VERSION ""

NS_ :

BS_:

BU_: VCU Telemetry ISA_Scale AMS User
VAL_TABLE_ AliveSignal 1 "ONLINE" 0 "OFFLINE" ;

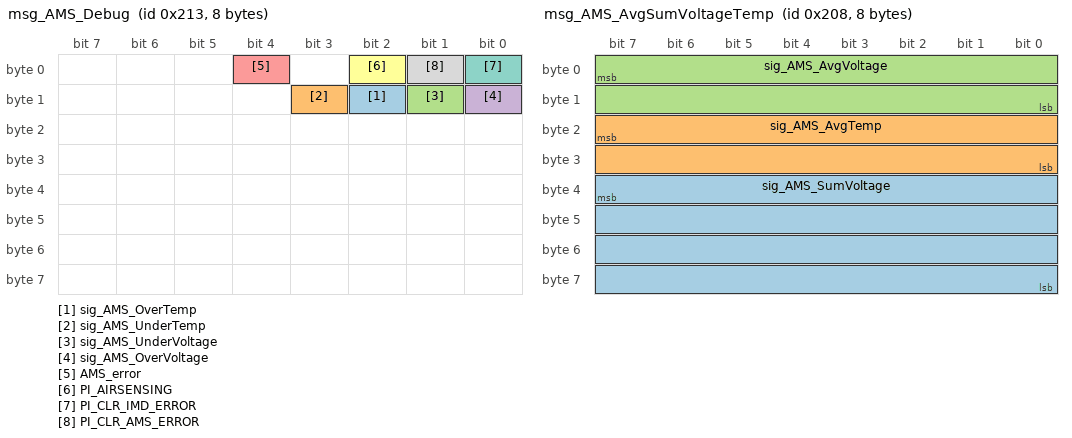
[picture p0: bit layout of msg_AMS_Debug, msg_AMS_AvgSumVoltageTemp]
BO_ 531 msg_AMS_Debug: 8 AMS
 SG_ sig_AMS_OverTemp : 10|1@0+ (1,0) [0|1] ""  VCU
 SG_ sig_AMS_UnderTemp : 11|1@0+ (1,0) [0|1] ""  VCU
 SG_ sig_AMS_UnderVoltage : 9|1@0+ (1,0) [0|1] ""  VCU
 SG_ sig_AMS_OverVoltage : 8|1@1+ (1,0) [0|1] ""  VCU
 SG_ AMS_error : 4|1@1+ (1,0) [0|0] ""  VCU
 SG_ PI_AIRSENSING : 2|1@1+ (1,0) [0|0] ""  VCU
 SG_ PI_CLR_IMD_ERROR : 0|1@1+ (1,0) [0|0] ""  VCU
 SG_ PI_CLR_AMS_ERROR : 1|1@1+ (1,0) [0|0] ""  VCU

BO_ 520 msg_AMS_AvgSumVoltageTemp: 8 AMS
 SG_ sig_AMS_SumVoltage : 39|32@0+ (0.0001,0) [0|429496.7295] ""  VCU
 SG_ sig_AMS_AvgTemp : 23|16@0+ (0.01,0) [0|65.535] ""  VCU
 SG_ sig_AMS_AvgVoltage : 7|16@0+ (0.0001,0) [0|6.5535] ""  VCU

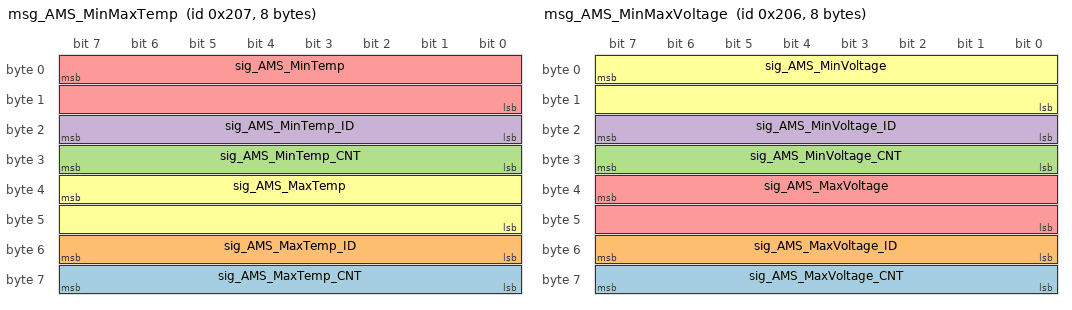
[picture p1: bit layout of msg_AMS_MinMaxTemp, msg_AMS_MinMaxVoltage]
BO_ 519 msg_AMS_MinMaxTemp: 8 AMS
 SG_ sig_AMS_MaxTemp_CNT : 63|8@0+ (1,0) [0|255] ""  VCU
 SG_ sig_AMS_MaxTemp_ID : 55|8@0+ (1,0) [0|255] ""  VCU
 SG_ sig_AMS_MinTemp_CNT : 31|8@0+ (1,0) [0|255] ""  VCU
 SG_ sig_AMS_MinTemp_ID : 23|8@0+ (1,0) [0|255] ""  VCU
 SG_ sig_AMS_MinTemp : 7|16@0+ (0.01,0) [0|65.535] ""  VCU
 SG_ sig_AMS_MaxTemp : 39|16@0+ (0.01,0) [0|65.535] ""  VCU

BO_ 518 msg_AMS_MinMaxVoltage: 8 AMS
 SG_ sig_AMS_MaxVoltage_CNT : 63|8@0+ (1,0) [0|255] ""  VCU
 SG_ sig_AMS_MaxVoltage_ID : 55|8@0+ (1,0) [0|255] ""  VCU
 SG_ sig_AMS_MinVoltage_CNT : 31|8@0+ (1,0) [0|255] ""  VCU
 SG_ sig_AMS_MinVoltage_ID : 23|8@0+ (1,0) [0|255] ""  VCU
 SG_ sig_AMS_MaxVoltage : 39|16@0+ (0.0001,0) [0|6.5535] "V"  VCU
 SG_ sig_AMS_MinVoltage : 7|16@0+ (0.0001,0) [0|6.5535] "V"  VCU

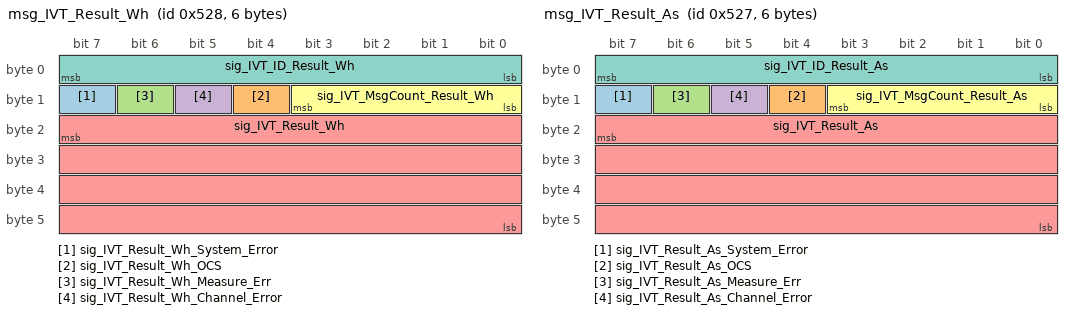
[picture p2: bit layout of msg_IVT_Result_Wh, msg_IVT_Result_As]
BO_ 1320 msg_IVT_Result_Wh: 6 ISA_Scale
 SG_ sig_IVT_Result_Wh_System_Error : 15|1@0+ (1,0) [0|0] ""  AMS
 SG_ sig_IVT_Result_Wh_OCS : 12|1@0+ (1,0) [0|0] ""  AMS
 SG_ sig_IVT_Result_Wh_Measure_Err : 14|1@0+ (1,0) [0|0] ""  AMS
 SG_ sig_IVT_Result_Wh_Channel_Error : 13|1@0+ (1,0) [0|0] ""  AMS
 SG_ sig_IVT_Result_Wh : 23|32@0- (1,0) [0|0] "Wh"  AMS
 SG_ sig_IVT_MsgCount_Result_Wh : 11|4@0+ (1,0) [0|0] ""  AMS
 SG_ sig_IVT_ID_Result_Wh : 7|8@0+ (1,0) [7|7] ""  AMS

BO_ 1319 msg_IVT_Result_As: 6 ISA_Scale
 SG_ sig_IVT_Result_As_System_Error : 15|1@0+ (1,0) [0|0] ""  AMS
 SG_ sig_IVT_Result_As_OCS : 12|1@0+ (1,0) [0|0] ""  AMS
 SG_ sig_IVT_Result_As_Measure_Err : 14|1@0+ (1,0) [0|0] ""  AMS
 SG_ sig_IVT_Result_As_Channel_Error : 13|1@0+ (1,0) [0|0] ""  AMS
 SG_ sig_IVT_Result_As : 23|32@0- (1,0) [0|0] "As"  AMS
 SG_ sig_IVT_MsgCount_Result_As : 11|4@0+ (1,0) [0|0] ""  AMS
 SG_ sig_IVT_ID_Result_As : 7|8@0+ (1,0) [6|6] ""  AMS

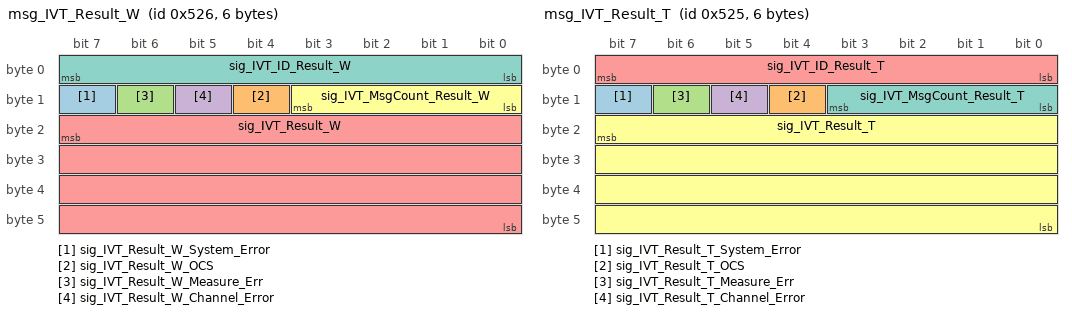
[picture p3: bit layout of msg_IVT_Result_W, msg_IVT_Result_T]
BO_ 1318 msg_IVT_Result_W: 6 ISA_Scale
 SG_ sig_IVT_Result_W_System_Error : 15|1@0+ (1,0) [0|0] ""  AMS
 SG_ sig_IVT_Result_W_OCS : 12|1@0+ (1,0) [0|0] ""  AMS
 SG_ sig_IVT_Result_W_Measure_Err : 14|1@0+ (1,0) [0|0] ""  AMS
 SG_ sig_IVT_Result_W_Channel_Error : 13|1@0+ (1,0) [0|0] ""  AMS
 SG_ sig_IVT_Result_W : 23|32@0- (1,0) [0|0] "W"  AMS
 SG_ sig_IVT_MsgCount_Result_W : 11|4@0+ (1,0) [0|0] ""  AMS
 SG_ sig_IVT_ID_Result_W : 7|8@0+ (1,0) [5|5] ""  AMS

BO_ 1317 msg_IVT_Result_T: 6 ISA_Scale
 SG_ sig_IVT_Result_T_System_Error : 15|1@0+ (1,0) [0|0] ""  AMS
 SG_ sig_IVT_Result_T_OCS : 12|1@0+ (1,0) [0|0] ""  AMS
 SG_ sig_IVT_Result_T_Measure_Err : 14|1@0+ (1,0) [0|0] ""  AMS
 SG_ sig_IVT_Result_T_Channel_Error : 13|1@0+ (1,0) [0|0] ""  AMS
 SG_ sig_IVT_ID_Result_T : 7|8@0+ (1,0) [4|4] ""  AMS
 SG_ sig_IVT_Result_T : 23|32@0- (1,0) [-32767|32768] "degC"  AMS
 SG_ sig_IVT_MsgCount_Result_T : 11|4@0+ (1,0) [0|0] ""  AMS

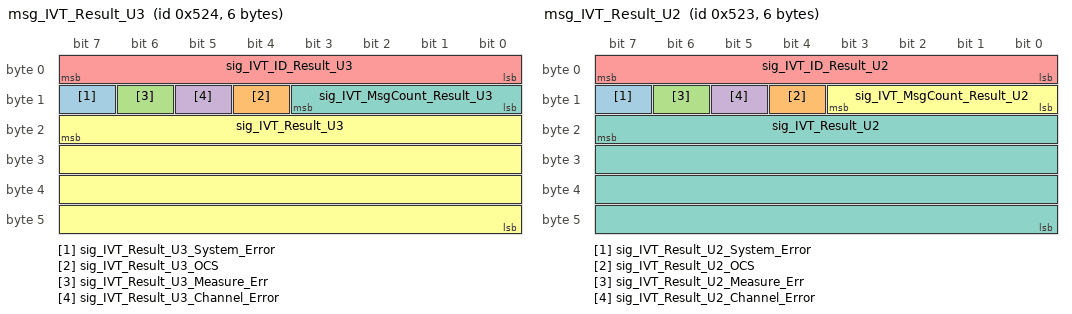
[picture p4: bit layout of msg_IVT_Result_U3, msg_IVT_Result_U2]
BO_ 1316 msg_IVT_Result_U3: 6 ISA_Scale
 SG_ sig_IVT_Result_U3_System_Error : 15|1@0+ (1,0) [0|0] ""  AMS
 SG_ sig_IVT_Result_U3_OCS : 12|1@0+ (1,0) [0|0] ""  AMS
 SG_ sig_IVT_Result_U3_Measure_Err : 14|1@0+ (1,0) [0|0] ""  AMS
 SG_ sig_IVT_Result_U3_Channel_Error : 13|1@0+ (1,0) [0|0] ""  AMS
 SG_ sig_IVT_ID_Result_U3 : 7|8@0+ (1,0) [3|3] ""  AMS
 SG_ sig_IVT_Result_U3 : 23|32@0- (1,0) [0|0] "mV"  AMS
 SG_ sig_IVT_MsgCount_Result_U3 : 11|4@0+ (1,0) [0|0] ""  AMS

BO_ 1315 msg_IVT_Result_U2: 6 ISA_Scale
 SG_ sig_IVT_Result_U2_System_Error : 15|1@0+ (1,0) [0|0] ""  AMS
 SG_ sig_IVT_Result_U2_OCS : 12|1@0+ (1,0) [0|0] ""  AMS
 SG_ sig_IVT_Result_U2_Measure_Err : 14|1@0+ (1,0) [0|0] ""  AMS
 SG_ sig_IVT_Result_U2_Channel_Error : 13|1@0+ (1,0) [0|0] ""  AMS
 SG_ sig_IVT_ID_Result_U2 : 7|8@0+ (1,0) [2|2] ""  AMS
 SG_ sig_IVT_MsgCount_Result_U2 : 11|4@0+ (1,0) [0|0] ""  AMS
 SG_ sig_IVT_Result_U2 : 23|32@0- (1,0) [0|0] "mV"  AMS

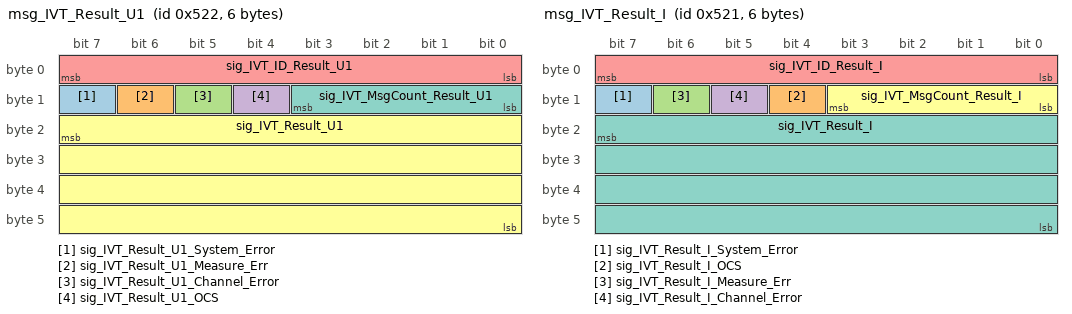
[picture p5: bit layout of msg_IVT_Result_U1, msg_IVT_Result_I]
BO_ 1314 msg_IVT_Result_U1: 6 ISA_Scale
 SG_ sig_IVT_Result_U1_System_Error : 15|1@0+ (1,0) [0|0] ""  AMS
 SG_ sig_IVT_Result_U1_Measure_Err : 14|1@0+ (1,0) [0|0] ""  AMS
 SG_ sig_IVT_Result_U1_Channel_Error : 13|1@0+ (1,0) [0|0] ""  AMS
 SG_ sig_IVT_Result_U1_OCS : 12|1@0+ (1,0) [0|0] ""  AMS
 SG_ sig_IVT_ID_Result_U1 : 7|8@0+ (1,0) [1|1] ""  AMS
 SG_ sig_IVT_Result_U1 : 23|32@0- (1,0) [0|0] "mV"  AMS
 SG_ sig_IVT_MsgCount_Result_U1 : 11|4@0+ (1,0) [0|0] ""  AMS

BO_ 1313 msg_IVT_Result_I: 6 ISA_Scale
 SG_ sig_IVT_Result_I_System_Error : 15|1@0+ (1,0) [0|0] ""  AMS
 SG_ sig_IVT_Result_I_OCS : 12|1@0+ (1,0) [0|0] ""  AMS
 SG_ sig_IVT_Result_I_Measure_Err : 14|1@0+ (1,0) [0|0] ""  AMS
 SG_ sig_IVT_Result_I_Channel_Error : 13|1@0+ (1,0) [0|0] ""  AMS
 SG_ sig_IVT_ID_Result_I : 7|8@0+ (1,0) [0|0] ""  AMS
 SG_ sig_IVT_MsgCount_Result_I : 11|4@0+ (1,0) [0|0] ""  AMS
 SG_ sig_IVT_Result_I : 23|32@0- (1,0) [0|0] "mA"  AMS

BO_ 1280 msg_AMS_Voltages: 7 AMS
 SG_ Voltage_Cell_144 m47 : 47|16@0+ (0.0001,0) [0|6.5535] "V"  VCU
 SG_ Voltage_Cell_143 m47 : 31|16@0+ (0.0001,0) [0|6.5535] "V"  VCU
 SG_ Voltage_Cell_142 m47 : 15|16@0+ (0.0001,0) [0|6.5535] "V"  VCU
 SG_ Voltage_Cell_141 m46 : 47|16@0+ (0.0001,0) [0|6.5535] "V"  VCU
 SG_ Voltage_Cell_140 m46 : 31|16@0+ (0.0001,0) [0|6.5535] "V"  VCU
 SG_ Voltage_Cell_139 m46 : 15|16@0+ (0.0001,0) [0|6.5535] "V"  VCU
 SG_ Voltage_Cell_138 m45 : 47|16@0+ (0.0001,0) [0|6.5535] "V"  VCU
 SG_ Voltage_Cell_137 m45 : 31|16@0+ (0.0001,0) [0|6.5535] "V"  VCU
 SG_ Voltage_Cell_136 m45 : 15|16@0+ (0.0001,0) [0|6.5535] "V"  VCU
 SG_ Voltage_Cell_135 m44 : 47|16@0+ (0.0001,0) [0|6.5535] "V"  VCU
 SG_ Voltage_Cell_134 m44 : 31|16@0+ (0.0001,0) [0|6.5535] "V"  VCU
 SG_ Voltage_Cell_133 m44 : 15|16@0+ (0.0001,0) [0|6.5535] "V"  VCU
 SG_ Voltage_Cell_132 m43 : 47|16@0+ (0.0001,0) [0|6.5535] "V"  VCU
 SG_ Voltage_Cell_131 m43 : 31|16@0+ (0.0001,0) [0|6.5535] "V"  VCU
 SG_ Voltage_Cell_130 m43 : 15|16@0+ (0.0001,0) [0|6.5535] "V"  VCU
 SG_ Voltage_Cell_129 m42 : 47|16@0+ (0.0001,0) [0|6.5535] "V"  VCU
 SG_ Voltage_Cell_128 m42 : 31|16@0+ (0.0001,0) [0|6.5535] "V"  VCU
 SG_ Voltage_Cell_127 m42 : 15|16@0+ (0.0001,0) [0|6.5535] "V"  VCU
 SG_ Voltage_Cell_126 m41 : 47|16@0+ (0.0001,0) [0|6.5535] "V"  VCU
 SG_ Voltage_Cell_125 m41 : 31|16@0+ (0.0001,0) [0|6.5535] "V"  VCU
 SG_ Voltage_Cell_124 m41 : 15|16@0+ (0.0001,0) [0|6.5535] "V"  VCU
 SG_ Voltage_Cell_123 m40 : 47|16@0+ (0.0001,0) [0|6.5535] "V"  VCU
 SG_ Voltage_Cell_122 m40 : 31|16@0+ (0.0001,0) [0|6.5535] "V"  VCU
 SG_ Voltage_Cell_121 m40 : 15|16@0+ (0.0001,0) [0|6.5535] "V"  VCU
 SG_ Voltage_Cell_120 m39 : 47|16@0+ (0.0001,0) [0|6.5535] "V"  VCU
 SG_ Voltage_Cell_119 m39 : 31|16@0+ (0.0001,0) [0|6.5535] "V"  VCU
 SG_ Voltage_Cell_118 m39 : 15|16@0+ (0.0001,0) [0|6.5535] "V"  VCU
 SG_ Voltage_Cell_117 m38 : 47|16@0+ (0.0001,0) [0|6.5535] "V"  VCU
 SG_ Voltage_Cell_116 m38 : 31|16@0+ (0.0001,0) [0|6.5535] "V"  VCU
 SG_ Voltage_Cell_115 m38 : 15|16@0+ (0.0001,0) [0|6.5535] "V"  VCU
 SG_ Voltage_Cell_114 m37 : 47|16@0+ (0.0001,0) [0|6.5535] "V"  VCU
 SG_ Voltage_Cell_113 m37 : 31|16@0+ (0.0001,0) [0|6.5535] "V"  VCU
 SG_ Voltage_Cell_112 m37 : 15|16@0+ (0.0001,0) [0|6.5535] "V"  VCU
 SG_ Voltage_Cell_111 m36 : 47|16@0+ (0.0001,0) [0|6.5535] "V"  VCU
 SG_ Voltage_Cell_110 m36 : 31|16@0+ (0.0001,0) [0|6.5535] "V"  VCU
 SG_ Voltage_Cell_109 m36 : 15|16@0+ (0.0001,0) [0|6.5535] "V"  VCU
 SG_ Voltage_Cell_108 m35 : 47|16@0+ (0.0001,0) [0|6.5535] "V"  VCU
 SG_ Voltage_Cell_107 m35 : 31|16@0+ (0.0001,0) [0|6.5535] "V"  VCU
 SG_ Voltage_Cell_106 m35 : 15|16@0+ (0.0001,0) [0|6.5535] "V"  VCU
 SG_ Voltage_Cell_105 m34 : 47|16@0+ (0.0001,0) [0|6.5535] "V"  VCU
 SG_ Voltage_Cell_104 m34 : 31|16@0+ (0.0001,0) [0|6.5535] "V"  VCU
 SG_ Voltage_Cell_103 m34 : 15|16@0+ (0.0001,0) [0|6.5535] "V"  VCU
 SG_ Voltage_Cell_102 m33 : 47|16@0+ (0.0001,0) [0|6.5535] "V"  VCU
 SG_ Voltage_Cell_101 m33 : 31|16@0+ (0.0001,0) [0|6.5535] "V"  VCU
 SG_ Voltage_Cell_100 m33 : 15|16@0+ (0.0001,0) [0|6.5535] "V"  VCU
 SG_ Voltage_Cell_099 m32 : 47|16@0+ (0.0001,0) [0|6.5535] "V"  VCU
 SG_ Voltage_Cell_098 m32 : 31|16@0+ (0.0001,0) [0|6.5535] "V"  VCU
 SG_ Voltage_Cell_097 m32 : 15|16@0+ (0.0001,0) [0|6.5535] "V"  VCU
 SG_ Voltage_Cell_096 m31 : 47|16@0+ (0.0001,0) [0|6.5535] "V"  VCU
 SG_ Voltage_Cell_095 m31 : 31|16@0+ (0.0001,0) [0|6.5535] "V"  VCU
 SG_ Voltage_Cell_094 m31 : 15|16@0+ (0.0001,0) [0|6.5535] "V"  VCU
 SG_ Voltage_Cell_093 m30 : 47|16@0+ (0.0001,0) [0|6.5535] "V"  VCU
 SG_ Voltage_Cell_092 m30 : 31|16@0+ (0.0001,0) [0|6.5535] "V"  VCU
 SG_ Voltage_Cell_091 m30 : 15|16@0+ (0.0001,0) [0|6.5535] "V"  VCU
 SG_ Voltage_Cell_090 m29 : 47|16@0+ (0.0001,0) [0|6.5535] "V"  VCU
 SG_ Voltage_Cell_089 m29 : 31|16@0+ (0.0001,0) [0|6.5535] "V"  VCU
 SG_ Voltage_Cell_088 m29 : 15|16@0+ (0.0001,0) [0|6.5535] "V"  VCU
 SG_ Voltage_Cell_087 m28 : 47|16@0+ (0.0001,0) [0|6.5535] "V"  VCU
 SG_ Voltage_Cell_086 m28 : 31|16@0+ (0.0001,0) [0|6.5535] "V"  VCU
 SG_ Voltage_Cell_085 m28 : 15|16@0+ (0.0001,0) [0|6.5535] "V"  VCU
 SG_ Voltage_Cell_084 m27 : 47|16@0+ (0.0001,0) [0|6.5535] "V"  VCU
 SG_ Voltage_Cell_083 m27 : 31|16@0+ (0.0001,0) [0|6.5535] "V"  VCU
 SG_ Voltage_Cell_082 m27 : 15|16@0+ (0.0001,0) [0|6.5535] "V"  VCU
 SG_ Voltage_Cell_081 m26 : 47|16@0+ (0.0001,0) [0|6.5535] "V"  VCU
 SG_ Voltage_Cell_080 m26 : 31|16@0+ (0.0001,0) [0|6.5535] "V"  VCU
 SG_ Voltage_Cell_079 m26 : 15|16@0+ (0.0001,0) [0|6.5535] "V"  VCU
 SG_ Voltage_Cell_078 m25 : 47|16@0+ (0.0001,0) [0|6.5535] "V"  VCU
 SG_ Voltage_Cell_077 m25 : 31|16@0+ (0.0001,0) [0|6.5535] "V"  VCU
 SG_ Voltage_Cell_076 m25 : 15|16@0+ (0.0001,0) [0|6.5535] "V"  VCU
 SG_ Voltage_Cell_075 m24 : 47|16@0+ (0.0001,0) [0|6.5535] "V"  VCU
 SG_ Voltage_Cell_074 m24 : 31|16@0+ (0.0001,0) [0|6.5535] "V"  VCU
 SG_ Voltage_Cell_073 m24 : 15|16@0+ (0.0001,0) [0|6.5535] "V"  VCU
 SG_ Voltage_Cell_072 m23 : 47|16@0+ (0.0001,0) [0|6.5535] "V"  VCU
 SG_ Voltage_Cell_071 m23 : 31|16@0+ (0.0001,0) [0|6.5535] "V"  VCU
 SG_ Voltage_Cell_070 m23 : 15|16@0+ (0.0001,0) [0|6.5535] "V"  VCU
 SG_ Voltage_Cell_069 m22 : 47|16@0+ (0.0001,0) [0|6.5535] "V"  VCU
 SG_ Voltage_Cell_068 m22 : 31|16@0+ (0.0001,0) [0|6.5535] "V"  VCU
 SG_ Voltage_Cell_067 m22 : 15|16@0+ (0.0001,0) [0|6.5535] "V"  VCU
 SG_ Voltage_Cell_066 m21 : 47|16@0+ (0.0001,0) [0|6.5535] "V"  VCU
 SG_ Voltage_Cell_065 m21 : 31|16@0+ (0.0001,0) [0|6.5535] "V"  VCU
 SG_ Voltage_Cell_064 m21 : 15|16@0+ (0.0001,0) [0|6.5535] "V"  VCU
 SG_ Voltage_Cell_063 m20 : 47|16@0+ (0.0001,0) [0|6.5535] "V"  VCU
 SG_ Voltage_Cell_062 m20 : 31|16@0+ (0.0001,0) [0|6.5535] "V"  VCU
 SG_ Voltage_Cell_061 m20 : 15|16@0+ (0.0001,0) [0|6.5535] "V"  VCU
 SG_ Voltage_Cell_060 m19 : 47|16@0+ (0.0001,0) [0|6.5535] "V"  VCU
 SG_ Voltage_Cell_059 m19 : 31|16@0+ (0.0001,0) [0|6.5535] "V"  VCU
 SG_ Voltage_Cell_058 m19 : 15|16@0+ (0.0001,0) [0|6.5535] "V"  VCU
 SG_ Voltage_Cell_057 m18 : 47|16@0+ (0.0001,0) [0|6.5535] "V"  VCU
 SG_ Voltage_Cell_056 m18 : 31|16@0+ (0.0001,0) [0|6.5535] "V"  VCU
 SG_ Voltage_Cell_055 m18 : 15|16@0+ (0.0001,0) [0|6.5535] "V"  VCU
 SG_ Voltage_Cell_054 m17 : 47|16@0+ (0.0001,0) [0|6.5535] "V"  VCU
 SG_ Voltage_Cell_053 m17 : 31|16@0+ (0.0001,0) [0|6.5535] "V"  VCU
 SG_ Voltage_Cell_052 m17 : 15|16@0+ (0.0001,0) [0|6.5535] "V"  VCU
 SG_ Voltage_Cell_051 m16 : 47|16@0+ (0.0001,0) [0|6.5535] "V"  VCU
 SG_ Voltage_Cell_050 m16 : 31|16@0+ (0.0001,0) [0|6.5535] "V"  VCU
 SG_ Voltage_Cell_049 m16 : 15|16@0+ (0.0001,0) [0|6.5535] "V"  VCU
 SG_ Voltage_Cell_048 m15 : 47|16@0+ (0.0001,0) [0|6.5535] "V"  VCU
 SG_ Voltage_Cell_047 m15 : 31|16@0+ (0.0001,0) [0|6.5535] "V"  VCU
 SG_ Voltage_Cell_046 m15 : 15|16@0+ (0.0001,0) [0|6.5535] "V"  VCU
 SG_ Voltage_Cell_045 m14 : 47|16@0+ (0.0001,0) [0|6.5535] "V"  VCU
 SG_ Voltage_Cell_044 m14 : 31|16@0+ (0.0001,0) [0|6.5535] "V"  VCU
 SG_ Voltage_Cell_043 m14 : 15|16@0+ (0.0001,0) [0|6.5535] "V"  VCU
 SG_ Voltage_Cell_042 m13 : 47|16@0+ (0.0001,0) [0|6.5535] "V"  VCU
 SG_ Voltage_Cell_041 m13 : 31|16@0+ (0.0001,0) [0|6.5535] "V"  VCU
 SG_ Voltage_Cell_040 m13 : 15|16@0+ (0.0001,0) [0|6.5535] "V"  VCU
 SG_ Voltage_Cell_039 m12 : 47|16@0+ (0.0001,0) [0|6.5535] "V"  VCU
 SG_ Voltage_Cell_038 m12 : 31|16@0+ (0.0001,0) [0|6.5535] "V"  VCU
 SG_ Voltage_Cell_037 m12 : 15|16@0+ (0.0001,0) [0|6.5535] "V"  VCU
 SG_ Voltage_Cell_036 m11 : 47|16@0+ (0.0001,0) [0|6.5535] "V"  VCU
 SG_ Voltage_Cell_035 m11 : 31|16@0+ (0.0001,0) [0|6.5535] "V"  VCU
 SG_ Voltage_Cell_034 m11 : 15|16@0+ (0.0001,0) [0|6.5535] "V"  VCU
 SG_ Voltage_Cell_033 m10 : 47|16@0+ (0.0001,0) [0|6.5535] "V"  VCU
 SG_ Voltage_Cell_032 m10 : 31|16@0+ (0.0001,0) [0|6.5535] "V"  VCU
 SG_ Voltage_Cell_031 m10 : 15|16@0+ (0.0001,0) [0|6.5535] "V"  VCU
 SG_ Voltage_Cell_030 m9 : 47|16@0+ (0.0001,0) [0|6.5535] "V"  VCU
 SG_ Voltage_Cell_029 m9 : 31|16@0+ (0.0001,0) [0|6.5535] "V"  VCU
 SG_ Voltage_Cell_028 m9 : 15|16@0+ (0.0001,0) [0|6.5535] "V"  VCU
 SG_ Voltage_Cell_027 m8 : 47|16@0+ (0.0001,0) [0|6.5535] "V"  VCU
 SG_ Voltage_Cell_026 m8 : 31|16@0+ (0.0001,0) [0|6.5535] "V"  VCU
 SG_ Voltage_Cell_025 m8 : 15|16@0+ (0.0001,0) [0|6.5535] "V"  VCU
 SG_ Voltage_Cell_024 m7 : 47|16@0+ (0.0001,0) [0|6.5535] "V"  VCU
 SG_ Voltage_Cell_023 m7 : 31|16@0+ (0.0001,0) [0|6.5535] "V"  VCU
 SG_ Voltage_Cell_022 m7 : 15|16@0+ (0.0001,0) [0|6.5535] "V"  VCU
 SG_ Voltage_Cell_021 m6 : 47|16@0+ (0.0001,0) [0|6.5535] "V"  VCU
 SG_ Voltage_Cell_020 m6 : 31|16@0+ (0.0001,0) [0|6.5535] "V"  VCU
 SG_ Voltage_Cell_019 m6 : 15|16@0+ (0.0001,0) [0|6.5535] "V"  VCU
 SG_ Voltage_Cell_018 m5 : 47|16@0+ (0.0001,0) [0|6.5535] "V"  VCU
 SG_ Voltage_Cell_017 m5 : 31|16@0+ (0.0001,0) [0|6.5535] "V"  VCU
 SG_ Voltage_Cell_016 m5 : 15|16@0+ (0.0001,0) [0|6.5535] "V"  VCU
 SG_ Voltage_Cell_015 m4 : 47|16@0+ (0.0001,0) [0|6.5535] "V"  VCU
 SG_ Voltage_Cell_014 m4 : 31|16@0+ (0.0001,0) [0|6.5535] "V"  VCU
 SG_ Voltage_Cell_013 m4 : 15|16@0+ (0.0001,0) [0|6.5535] "V"  VCU
 SG_ Voltage_Cell_012 m3 : 47|16@0+ (0.0001,0) [0|6.5535] "V"  VCU
 SG_ Voltage_Cell_011 m3 : 31|16@0+ (0.0001,0) [0|6.5535] "V"  VCU
 SG_ Voltage_Cell_010 m3 : 15|16@0+ (0.0001,0) [0|6.5535] "V"  VCU
 SG_ Voltage_Cell_009 m2 : 47|16@0+ (0.0001,0) [0|6.5535] "V"  VCU
 SG_ Voltage_Cell_008 m2 : 31|16@0+ (0.0001,0) [0|6.5535] "V"  VCU
 SG_ Voltage_Cell_007 m2 : 15|16@0+ (0.0001,0) [0|6.5535] "V"  VCU
 SG_ Voltage_Cell_006 m1 : 47|16@0+ (0.0001,0) [0|6.5535] "V"  VCU
 SG_ Voltage_Cell_005 m1 : 31|16@0+ (0.0001,0) [0|6.5535] "V"  VCU
 SG_ Voltage_Cell_004 m1 : 15|16@0+ (0.0001,0) [0|6.5535] "V"  VCU
 SG_ Voltage_Cell_003 m0 : 47|16@0+ (0.0001,0) [0|6.5535] "V"  VCU
 SG_ Voltage_Cell_002 m0 : 31|16@0+ (0.0001,0) [0|6.5535] "V"  VCU
 SG_ Voltage_Cell_001 m0 : 15|16@0+ (0.0001,0) [0|6.5535] "V"  VCU
 SG_ Multiplexor_Voltages M : 7|8@0+ (1,0) [0|35] ""  VCU

BO_ 1281 msg_AMS_Temps: 7 AMS
 SG_ Temp_Cell_003 m0 : 47|16@0+ (0.01,0) [0|65.535] "degC"  VCU
 SG_ Temp_Cell_144 m47 : 47|16@0+ (0.01,0) [0|65.535] "degC"  VCU
 SG_ Temp_Cell_143 m47 : 31|16@0+ (0.01,0) [0|65.535] "degC"  VCU
 SG_ Temp_Cell_142 m47 : 15|16@0+ (0.01,0) [0|65.535] "degC"  VCU
 SG_ Temp_Cell_141 m46 : 47|16@0+ (0.01,0) [0|65.535] "degC"  VCU
 SG_ Temp_Cell_140 m46 : 31|16@0+ (0.01,0) [0|65.535] "degC"  VCU
 SG_ Temp_Cell_139 m46 : 15|16@0+ (0.01,0) [0|65.535] "degC"  VCU
 SG_ Temp_Cell_138 m45 : 47|16@0+ (0.01,0) [0|65.535] "degC"  VCU
 SG_ Temp_Cell_137 m45 : 31|16@0+ (0.01,0) [0|65.535] "degC"  VCU
 SG_ Temp_Cell_136 m45 : 15|16@0+ (0.01,0) [0|65.535] "degC"  VCU
 SG_ Temp_Cell_135 m44 : 47|16@0+ (0.01,0) [0|65.535] "degC"  VCU
 SG_ Temp_Cell_134 m44 : 31|16@0+ (0.01,0) [0|65.535] "degC"  VCU
 SG_ Temp_Cell_133 m44 : 15|16@0+ (0.01,0) [0|65.535] "degC"  VCU
 SG_ Temp_Cell_132 m43 : 47|16@0+ (0.01,0) [0|65.535] "degC"  VCU
 SG_ Temp_Cell_131 m43 : 31|16@0+ (0.01,0) [0|65.535] "degC"  VCU
 SG_ Temp_Cell_130 m43 : 15|16@0+ (0.01,0) [0|65.535] "degC"  VCU
 SG_ Temp_Cell_129 m42 : 47|16@0+ (0.01,0) [0|65.535] "degC"  VCU
 SG_ Temp_Cell_128 m42 : 31|16@0+ (0.01,0) [0|65.535] "degC"  VCU
 SG_ Temp_Cell_127 m42 : 15|16@0+ (0.01,0) [0|65.535] "degC"  VCU
 SG_ Temp_Cell_126 m41 : 47|16@0+ (0.01,0) [0|65.535] "degC"  VCU
 SG_ Temp_Cell_125 m41 : 31|16@0+ (0.01,0) [0|65.535] "degC"  VCU
 SG_ Temp_Cell_124 m41 : 15|16@0+ (0.01,0) [0|65.535] "degC"  VCU
 SG_ Temp_Cell_123 m40 : 47|16@0+ (0.01,0) [0|65.535] "degC"  VCU
 SG_ Temp_Cell_122 m40 : 31|16@0+ (0.01,0) [0|65.535] "degC"  VCU
 SG_ Temp_Cell_121 m40 : 15|16@0+ (0.01,0) [0|65.535] "degC"  VCU
 SG_ Temp_Cell_120 m39 : 47|16@0+ (0.01,0) [0|65.535] "degC"  VCU
 SG_ Temp_Cell_119 m39 : 31|16@0+ (0.01,0) [0|65.535] "degC"  VCU
 SG_ Temp_Cell_118 m39 : 15|16@0+ (0.01,0) [0|65.535] "degC"  VCU
 SG_ Temp_Cell_117 m38 : 47|16@0+ (0.01,0) [0|65.535] "degC"  VCU
 SG_ Temp_Cell_116 m38 : 31|16@0+ (0.01,0) [0|65.535] "degC"  VCU
 SG_ Temp_Cell_115 m38 : 15|16@0+ (0.01,0) [0|65.535] "degC"  VCU
 SG_ Temp_Cell_114 m37 : 47|16@0+ (0.01,0) [0|65.535] "degC"  VCU
 SG_ Temp_Cell_113 m37 : 31|16@0+ (0.01,0) [0|65.535] "degC"  VCU
 SG_ Temp_Cell_112 m37 : 15|16@0+ (0.01,0) [0|65.535] "degC"  VCU
 SG_ Temp_Cell_111 m36 : 47|16@0+ (0.01,0) [0|65.535] "degC"  VCU
 SG_ Temp_Cell_110 m36 : 31|16@0+ (0.01,0) [0|65.535] "degC"  VCU
 SG_ Temp_Cell_109 m36 : 15|16@0+ (0.01,0) [0|65.535] "degC"  VCU
 SG_ Temp_Cell_108 m35 : 47|16@0+ (0.01,0) [0|65.535] "degC"  VCU
 SG_ Temp_Cell_107 m35 : 31|16@0+ (0.01,0) [0|65.535] "degC"  VCU
 SG_ Temp_Cell_106 m35 : 15|16@0+ (0.01,0) [0|65.535] "degC"  VCU
 SG_ Temp_Cell_105 m34 : 47|16@0+ (0.01,0) [0|65.535] "degC"  VCU
 SG_ Temp_Cell_104 m34 : 31|16@0+ (0.01,0) [0|65.535] "degC"  VCU
 SG_ Temp_Cell_103 m34 : 15|16@0+ (0.01,0) [0|65.535] "degC"  VCU
 SG_ Temp_Cell_102 m33 : 47|16@0+ (0.01,0) [0|65.535] "degC"  VCU
 SG_ Temp_Cell_101 m33 : 31|16@0+ (0.01,0) [0|65.535] "degC"  VCU
 SG_ Temp_Cell_100 m33 : 15|16@0+ (0.01,0) [0|65.535] "degC"  VCU
 SG_ Temp_Cell_099 m32 : 47|16@0+ (0.01,0) [0|65.535] "degC"  VCU
 SG_ Temp_Cell_098 m32 : 31|16@0+ (0.01,0) [0|65.535] "degC"  VCU
 SG_ Temp_Cell_097 m32 : 15|16@0+ (0.01,0) [0|65.535] "degC"  VCU
 SG_ Temp_Cell_096 m31 : 47|16@0+ (0.01,0) [0|65.535] "degC"  VCU
 SG_ Temp_Cell_095 m31 : 31|16@0+ (0.01,0) [0|65.535] "degC"  VCU
 SG_ Temp_Cell_094 m31 : 15|16@0+ (0.01,0) [0|65.535] "degC"  VCU
 SG_ Temp_Cell_093 m30 : 47|16@0+ (0.01,0) [0|65.535] "degC"  VCU
 SG_ Temp_Cell_092 m30 : 31|16@0+ (0.01,0) [0|65.535] "degC"  VCU
 SG_ Temp_Cell_091 m30 : 15|16@0+ (0.01,0) [0|65.535] "degC"  VCU
 SG_ Temp_Cell_090 m29 : 47|16@0+ (0.01,0) [0|65.535] "degC"  VCU
 SG_ Temp_Cell_089 m29 : 31|16@0+ (0.01,0) [0|65.535] "degC"  VCU
 SG_ Temp_Cell_088 m29 : 15|16@0+ (0.01,0) [0|65.535] "degC"  VCU
 SG_ Temp_Cell_087 m28 : 47|16@0+ (0.01,0) [0|65.535] "degC"  VCU
 SG_ Temp_Cell_086 m28 : 31|16@0+ (0.01,0) [0|65.535] "degC"  VCU
 SG_ Temp_Cell_085 m28 : 15|16@0+ (0.01,0) [0|65.535] "degC"  VCU
 SG_ Temp_Cell_084 m27 : 47|16@0+ (0.01,0) [0|65.535] "degC"  VCU
 SG_ Temp_Cell_083 m27 : 31|16@0+ (0.01,0) [0|65.535] "degC"  VCU
 SG_ Temp_Cell_082 m27 : 15|16@0+ (0.01,0) [0|65.535] "degC"  VCU
 SG_ Temp_Cell_081 m26 : 47|16@0+ (0.01,0) [0|65.535] "degC"  VCU
 SG_ Temp_Cell_080 m26 : 31|16@0+ (0.01,0) [0|65.535] "degC"  VCU
 SG_ Temp_Cell_079 m26 : 15|16@0+ (0.01,0) [0|65.535] "degC"  VCU
 SG_ Temp_Cell_078 m25 : 47|16@0+ (0.01,0) [0|65.535] "degC"  VCU
 SG_ Temp_Cell_077 m25 : 31|16@0+ (0.01,0) [0|65.535] "degC"  VCU
 SG_ Temp_Cell_076 m25 : 15|16@0+ (0.01,0) [0|65.535] "degC"  VCU
 SG_ Temp_Cell_075 m24 : 47|16@0+ (0.01,0) [0|65.535] "degC"  VCU
 SG_ Temp_Cell_074 m24 : 31|16@0+ (0.01,0) [0|65.535] "degC"  VCU
 SG_ Temp_Cell_073 m24 : 15|16@0+ (0.01,0) [0|65.535] "degC"  VCU
 SG_ Temp_Cell_072 m23 : 47|16@0+ (0.01,0) [0|65.535] "degC"  VCU
 SG_ Temp_Cell_071 m23 : 31|16@0+ (0.01,0) [0|65.535] "degC"  VCU
 SG_ Temp_Cell_070 m23 : 15|16@0+ (0.01,0) [0|65.535] "degC"  VCU
 SG_ Temp_Cell_069 m22 : 47|16@0+ (0.01,0) [0|65.535] "degC"  VCU
 SG_ Temp_Cell_068 m22 : 31|16@0+ (0.01,0) [0|65.535] "degC"  VCU
 SG_ Temp_Cell_067 m22 : 15|16@0+ (0.01,0) [0|65.535] "degC"  VCU
 SG_ Temp_Cell_066 m21 : 47|16@0+ (0.01,0) [0|65.535] "degC"  VCU
 SG_ Temp_Cell_065 m21 : 31|16@0+ (0.01,0) [0|65.535] "degC"  VCU
 SG_ Temp_Cell_064 m21 : 15|16@0+ (0.01,0) [0|65.535] "degC"  VCU
 SG_ Temp_Cell_063 m20 : 47|16@0+ (0.01,0) [0|65.535] "degC"  VCU
 SG_ Temp_Cell_062 m20 : 31|16@0+ (0.01,0) [0|65.535] "degC"  VCU
 SG_ Temp_Cell_061 m20 : 15|16@0+ (0.01,0) [0|65.535] "degC"  VCU
 SG_ Temp_Cell_060 m19 : 47|16@0+ (0.01,0) [0|65.535] "degC"  VCU
 SG_ Temp_Cell_059 m19 : 31|16@0+ (0.01,0) [0|65.535] "degC"  VCU
 SG_ Temp_Cell_058 m19 : 15|16@0+ (0.01,0) [0|65.535] "degC"  VCU
 SG_ Temp_Cell_057 m18 : 47|16@0+ (0.01,0) [0|65.535] "degC"  VCU
 SG_ Temp_Cell_056 m18 : 31|16@0+ (0.01,0) [0|65.535] "degC"  VCU
 SG_ Temp_Cell_055 m18 : 15|16@0+ (0.01,0) [0|65.535] "degC"  VCU
 SG_ Temp_Cell_054 m17 : 47|16@0+ (0.01,0) [0|65.535] "degC"  VCU
 SG_ Temp_Cell_053 m17 : 31|16@0+ (0.01,0) [0|65.535] "degC"  VCU
 SG_ Temp_Cell_052 m17 : 15|16@0+ (0.01,0) [0|65.535] "degC"  VCU
 SG_ Temp_Cell_051 m16 : 47|16@0+ (0.01,0) [0|65.535] "degC"  VCU
 SG_ Temp_Cell_050 m16 : 31|16@0+ (0.01,0) [0|65.535] "degC"  VCU
 SG_ Temp_Cell_049 m16 : 15|16@0+ (0.01,0) [0|65.535] "degC"  VCU
 SG_ Temp_Cell_048 m15 : 47|16@0+ (0.01,0) [0|65.535] "degC"  VCU
 SG_ Temp_Cell_047 m15 : 31|16@0+ (0.01,0) [0|65.535] "degC"  VCU
 SG_ Temp_Cell_046 m15 : 15|16@0+ (0.01,0) [0|65.535] "degC"  VCU
 SG_ Temp_Cell_045 m14 : 47|16@0+ (0.01,0) [0|65.535] "degC"  VCU
 SG_ Temp_Cell_044 m14 : 31|16@0+ (0.01,0) [0|65.535] "degC"  VCU
 SG_ Temp_Cell_043 m14 : 15|16@0+ (0.01,0) [0|65.535] "degC"  VCU
 SG_ Temp_Cell_042 m13 : 47|16@0+ (0.01,0) [0|65.535] "degC"  VCU
 SG_ Temp_Cell_041 m13 : 31|16@0+ (0.01,0) [0|65.535] "degC"  VCU
 SG_ Temp_Cell_040 m13 : 15|16@0+ (0.01,0) [0|65.535] "degC"  VCU
 SG_ Temp_Cell_039 m12 : 47|16@0+ (0.01,0) [0|65.535] "degC"  VCU
 SG_ Temp_Cell_038 m12 : 31|16@0+ (0.01,0) [0|65.535] "degC"  VCU
 SG_ Temp_Cell_037 m12 : 15|16@0+ (0.01,0) [0|65.535] "degC"  VCU
 SG_ Temp_Cell_036 m11 : 47|16@0+ (0.01,0) [0|65.535] "degC"  VCU
 SG_ Temp_Cell_035 m11 : 31|16@0+ (0.01,0) [0|65.535] "degC"  VCU
 SG_ Temp_Cell_034 m11 : 15|16@0+ (0.01,0) [0|65.535] "degC"  VCU
 SG_ Temp_Cell_033 m10 : 47|16@0+ (0.01,0) [0|65.535] "degC"  VCU
 SG_ Temp_Cell_032 m10 : 31|16@0+ (0.01,0) [0|65.535] "degC"  VCU
 SG_ Temp_Cell_031 m10 : 15|16@0+ (0.01,0) [0|65.535] "degC"  VCU
 SG_ Temp_Cell_030 m9 : 47|16@0+ (0.01,0) [0|65.535] "degC"  VCU
 SG_ Temp_Cell_029 m9 : 31|16@0+ (0.01,0) [0|65.535] "degC"  VCU
 SG_ Temp_Cell_028 m9 : 15|16@0+ (0.01,0) [0|65.535] "degC"  VCU
 SG_ Temp_Cell_027 m8 : 47|16@0+ (0.01,0) [0|65.535] "degC"  VCU
 SG_ Temp_Cell_026 m8 : 31|16@0+ (0.01,0) [0|65.535] "degC"  VCU
 SG_ Temp_Cell_025 m8 : 15|16@0+ (0.01,0) [0|65.535] "degC"  VCU
 SG_ Temp_Cell_024 m7 : 47|16@0+ (0.01,0) [0|65.535] "degC"  VCU
 SG_ Temp_Cell_023 m7 : 31|16@0+ (0.01,0) [0|65.535] "degC"  VCU
 SG_ Temp_Cell_022 m7 : 15|16@0+ (0.01,0) [0|65.535] "degC"  VCU
 SG_ Temp_Cell_021 m6 : 47|16@0+ (0.01,0) [0|65.535] "degC"  VCU
 SG_ Temp_Cell_020 m6 : 31|16@0+ (0.01,0) [0|65.535] "degC"  VCU
 SG_ Temp_Cell_019 m6 : 15|16@0+ (0.01,0) [0|65.535] "degC"  VCU
 SG_ Temp_Cell_018 m5 : 47|16@0+ (0.01,0) [0|65.535] "degC"  VCU
 SG_ Temp_Cell_017 m5 : 31|16@0+ (0.01,0) [0|65.535] "degC"  VCU
 SG_ Temp_Cell_016 m5 : 15|16@0+ (0.01,0) [0|65.535] "degC"  VCU
 SG_ Temp_Cell_015 m4 : 47|16@0+ (0.01,0) [0|65.535] "degC"  VCU
 SG_ Temp_Cell_014 m4 : 31|16@0+ (0.01,0) [0|65.535] "degC"  VCU
 SG_ Temp_Cell_013 m4 : 15|16@0+ (0.01,0) [0|65.535] "degC"  VCU
 SG_ Temp_Cell_012 m3 : 47|16@0+ (0.01,0) [0|65.535] "degC"  VCU
 SG_ Temp_Cell_011 m3 : 31|16@0+ (0.01,0) [0|65.535] "degC"  VCU
 SG_ Temp_Cell_010 m3 : 15|16@0+ (0.01,0) [0|65.535] "degC"  VCU
 SG_ Temp_Cell_009 m2 : 47|16@0+ (0.01,0) [0|65.535] "degC"  VCU
 SG_ Temp_Cell_008 m2 : 31|16@0+ (0.01,0) [0|65.535] "degC"  VCU
 SG_ Temp_Cell_007 m2 : 15|16@0+ (0.01,0) [0|65.535] "degC"  VCU
 SG_ Temp_Cell_006 m1 : 47|16@0+ (0.01,0) [0|65.535] "degC"  VCU
 SG_ Temp_Cell_005 m1 : 31|16@0+ (0.01,0) [0|65.535] "degC"  VCU
 SG_ Temp_Cell_004 m1 : 15|16@0+ (0.01,0) [0|65.535] "degC"  VCU
 SG_ Temp_Cell_002 m0 : 31|16@0+ (0.01,0) [0|65.535] "degC"  VCU
 SG_ Temp_Cell_001 m0 : 15|16@0+ (0.01,0) [0|65.535] "degC"  VCU
 SG_ Multiplexor_Temp M : 7|8@0+ (1,0) [0|35] ""  VCU

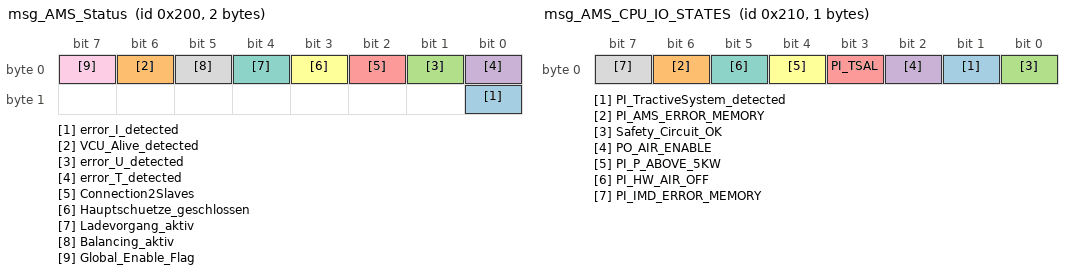
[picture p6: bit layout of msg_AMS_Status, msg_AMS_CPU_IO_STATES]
BO_ 512 msg_AMS_Status: 2 AMS
 SG_ error_I_detected : 8|1@1+ (1,0) [0|1] "" VCU
 SG_ VCU_Alive_detected : 6|1@1+ (1,0) [0|1] ""  VCU
 SG_ error_U_detected : 1|1@0+ (1,0) [0|0] ""  VCU
 SG_ error_T_detected : 0|1@0+ (1,0) [0|0] ""  VCU
 SG_ Connection2Slaves : 2|1@0+ (1,0) [0|0] ""  VCU
 SG_ Hauptschuetze_geschlossen : 3|1@0+ (1,0) [0|0] ""  VCU
 SG_ Ladevorgang_aktiv : 4|1@0+ (1,0) [0|0] ""  VCU
 SG_ Balancing_aktiv : 5|1@0+ (1,0) [0|0] ""  VCU
 SG_ Global_Enable_Flag : 7|1@0+ (1,0) [0|1] ""  VCU

BO_ 514 msg_AMS_Alive: 1 AMS
 SG_ AMS_Alive : 0|1@0+ (1,0) [0|0] ""  VCU

BO_ 528 msg_AMS_CPU_IO_STATES: 1 AMS
 SG_ PI_TractiveSystem_detected : 1|1@1+ (1,0) [0|1] ""  VCU
 SG_ PI_AMS_ERROR_MEMORY : 6|1@1+ (1,0) [0|1] ""  VCU
 SG_ Safety_Circuit_OK : 0|1@0+ (1,0) [0|0] ""  VCU
 SG_ PO_AIR_ENABLE : 2|1@0+ (1,0) [0|0] ""  VCU
 SG_ PI_TSAL : 3|1@0+ (1,0) [0|0] ""  VCU
 SG_ PI_P_ABOVE_5KW : 4|1@0+ (1,0) [0|0] ""  VCU
 SG_ PI_HW_AIR_OFF : 5|1@0+ (1,0) [0|0] ""  VCU
 SG_ PI_IMD_ERROR_MEMORY : 7|1@0+ (1,0) [0|0] ""  VCU

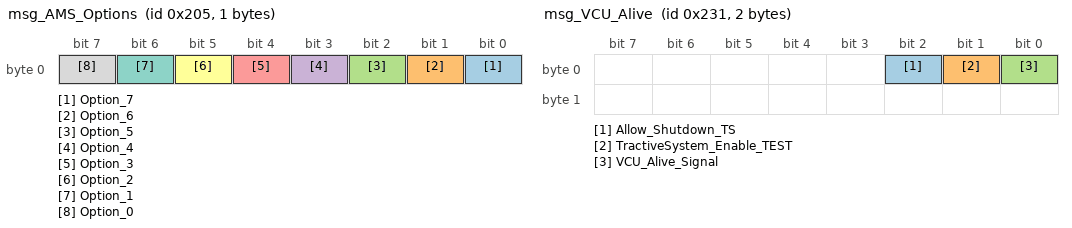
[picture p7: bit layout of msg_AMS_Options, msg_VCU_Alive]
BO_ 517 msg_AMS_Options: 1 AMS
 SG_ Option_7 : 0|1@0+ (1,0) [0|0] ""  VCU
 SG_ Option_6 : 1|1@0+ (1,0) [0|0] ""  VCU
 SG_ Option_5 : 2|1@0+ (1,0) [0|0] ""  VCU
 SG_ Option_4 : 3|1@0+ (1,0) [0|0] ""  VCU
 SG_ Option_3 : 4|1@0+ (1,0) [0|0] ""  VCU
 SG_ Option_2 : 5|1@0+ (1,0) [0|0] ""  VCU
 SG_ Option_1 : 6|1@0+ (1,0) [0|0] ""  VCU
 SG_ Option_0 : 7|1@0+ (1,0) [0|0] ""  VCU

BO_ 561 msg_VCU_Alive: 2 VCU
 SG_ Allow_Shutdown_TS : 2|1@1+ (1,0) [0|1] ""  AMS
 SG_ TractiveSystem_Enable_TEST : 1|1@1+ (1,0) [0|1] ""  AMS
 SG_ VCU_Alive_Signal : 0|1@0+ (1,0) [0|0] ""  AMS

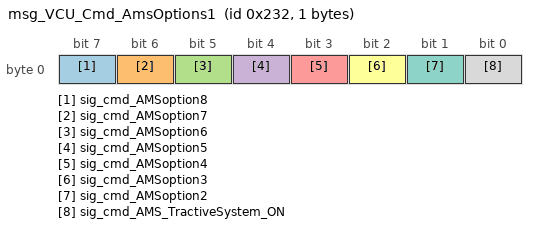
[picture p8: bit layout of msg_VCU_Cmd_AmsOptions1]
BO_ 562 msg_VCU_Cmd_AmsOptions1: 1 VCU
 SG_ sig_cmd_AMSoption8 : 7|1@1+ (1,0) [0|0] ""  AMS
 SG_ sig_cmd_AMSoption7 : 6|1@1+ (1,0) [0|0] ""  AMS
 SG_ sig_cmd_AMSoption6 : 5|1@1+ (1,0) [0|0] ""  AMS
 SG_ sig_cmd_AMSoption5 : 4|1@1+ (1,0) [0|0] ""  AMS
 SG_ sig_cmd_AMSoption4 : 3|1@1+ (1,0) [0|0] ""  AMS
 SG_ sig_cmd_AMSoption3 : 2|1@1+ (1,0) [0|0] ""  AMS
 SG_ sig_cmd_AMSoption2 : 1|1@1+ (1,0) [0|0] ""  AMS
 SG_ sig_cmd_AMS_TractiveSystem_ON : 0|1@1+ (1,0) [0|0] ""  AMS

CM_ BU_ ISA_Scale "ISA Scale - Stromsensor";
CM_ BU_ User "externer Entwickler z.B. mit CANoe";
BA_DEF_  "BusType" STRING ;
BA_DEF_DEF_  "BusType" "";
BA_ "BusType" "CAN";
VAL_ 561 VCU_Alive_Signal 1 "ONLINE" 0 "OFFLINE" ;
